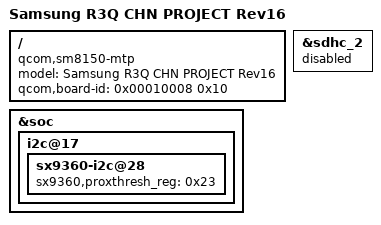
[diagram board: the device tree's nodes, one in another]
/* Copyright (c) 2016-2017, The Linux Foundation. All rights reserved.
 *
 * This program is free software; you can redistribute it and/or modify
 * it under the terms of the GNU General Public License version 2 and
 * only version 2 as published by the Free Software Foundation.
 *
 * This program is distributed in the hope that it will be useful,
 * but WITHOUT ANY WARRANTY; without even the implied warranty of
 * MERCHANTABILITY or FITNESS FOR A PARTICULAR PURPOSE.  See the
 * GNU General Public License for more details.
 */

/dts-v1/;
/plugin/;

#include <dt-bindings/clock/qcom,gcc-sm8150.h>
#include <dt-bindings/clock/qcom,camcc-sm8150.h>
#include <dt-bindings/clock/qcom,rpmh.h>
#include <dt-bindings/interrupt-controller/arm-gic.h>

#include "../qcom/sm8150-mtp.dtsi"
#include "../qcom/sdx5xm-external-soc.dtsi"
#include "../qcom/sm8150-sdx50m.dtsi"
#include "sm8150-sec-common.dtsi"
#include "sm8150-sec-r3q-pm-common.dtsi"
#include "sm8150-sec-r3q-input-common.dtsi"
#include "sm8150-sec-r3q-r03.dtsi"
#include "sm8150-sec-r3q-pinctrl-r03.dtsi"
#include "sm8150-sec-r3q-display-r00.dtsi"
#include "sm8150-sec-r3q-mst-r00.dtsi"
#include "sm8150-sec-r3q-displayport-r03.dtsi"
#include "battery-data-r3q-common.dtsi"
#include "sm8150-max77705.dtsi"
#include "sm8150-max77705-motor.dtsi"
#include "sm8150-sec-beyond2qlte-sensor-common.dtsi"
#include "sm8150-sec-r3q-fingerprint-sensor-r00.dtsi"
#include "sm8150-camera-sensor-r3q-r00.dtsi"
#include "sm8150-sec-r3q-nfc-r00.dtsi"

/ {
	model = "Samsung R3Q CHN PROJECT Rev16";
	compatible = "qcom,sm8150-mtp", "qcom,sm8150", "qcom,mtp";
	qcom,board-id = <0x00010008 0x10>;
};

&soc {
	i2c@17 { /* SW I2C */
		status = "ok";
		sx9360-i2c@28 {
			sx9360,proxthresh_reg = <0x23>; /* threshhold : 612 */
		};
	};
};

&sdhc_2 {
		status = "disabled";
};
